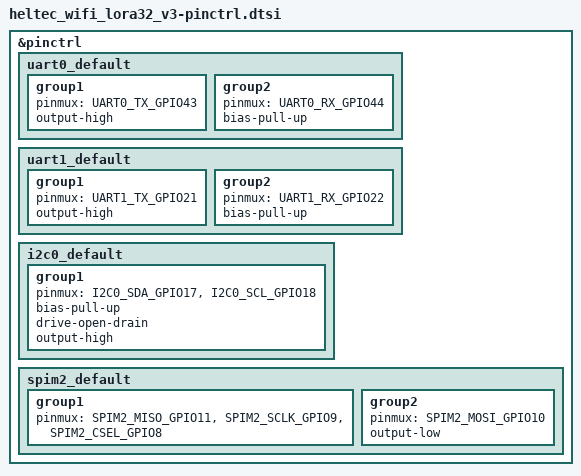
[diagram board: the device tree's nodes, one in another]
/*
 * SPDX-License-Identifier: GPL-3.0-or-later
 * SPDX-FileCopyrightText: The contributors to the LICHEN project
 *
 * Heltec WiFi LoRa 32 V3 — ESP32-S3FN8 pin assignments.
 * Pin data sourced from Heltec schematics v3.0 and cross-checked
 * against the Meshtastic firmware (variants/heltec_v3/variant.h).
 */

#include <zephyr/dt-bindings/pinctrl/esp-pinctrl-common.h>
#include <dt-bindings/pinctrl/esp32s3-pinctrl.h>
#include <zephyr/dt-bindings/pinctrl/esp32s3-gpio-sigmap.h>

&pinctrl {
	/* UART0: debug console — TX=GPIO43, RX=GPIO44 */
	uart0_default: uart0_default {
		group1 {
			pinmux = <UART0_TX_GPIO43>;
			output-high;
		};
		group2 {
			pinmux = <UART0_RX_GPIO44>;
			bias-pull-up;
		};
	};

	/*
	 * UART1: always-enabled bench console (non-destructive, dtr/rts=false; ref codereview bead project-LICHEN-g38y). GPIO21 TX / GPIO22 RX. No conflicts. See project-LICHEN-xb92.
	 */
	uart1_default: uart1_default {
		group1 {
			pinmux = <UART1_TX_GPIO21>;
			output-high;
		};
		group2 {
			pinmux = <UART1_RX_GPIO22>;
			bias-pull-up;
		};
	};

	/*
	 * I2C0: SSD1306 OLED display — SDA=GPIO17, SCL=GPIO18
	 * Disabled by default; enable via app overlay.
	 */
	i2c0_default: i2c0_default {
		group1 {
			pinmux = <I2C0_SDA_GPIO17>,
				 <I2C0_SCL_GPIO18>;
			bias-pull-up;
			drive-open-drain;
			output-high;
		};
	};

	/*
	 * SPI2: SX1262 LoRa radio
	 *   SCK=GPIO9  MOSI=GPIO10  MISO=GPIO11  CS=GPIO8
	 *   RESET=GPIO12  BUSY=GPIO13  DIO1=GPIO14
	 */
	spim2_default: spim2_default {
		group1 {
			pinmux = <SPIM2_MISO_GPIO11>,
				 <SPIM2_SCLK_GPIO9>,
				 <SPIM2_CSEL_GPIO8>;
		};
		group2 {
			pinmux = <SPIM2_MOSI_GPIO10>;
			output-low;
		};
	};

	/*
	 * UART1: spare console for bench use (non-destructive monitoring).
	 * Pins: GPIO21 (TX) / GPIO22 (RX) — avoids CP2102 auto-reset circuit
	 * on port open (lora_ipv6_mesh-9ia2). Use with external USB-UART
	 * adapter (TX-adapter to board-RX, RX-adapter to board-TX). Onboard
	 * CP2102/UART0 for boot messages only.
	 */
	uart1_default: uart1_default {
		group1 {
			pinmux = <UART1_TX_GPIO21>;
			output-high;
		};
		group2 {
			pinmux = <UART1_RX_GPIO22>;
			bias-pull-up;
		};
	};
};
